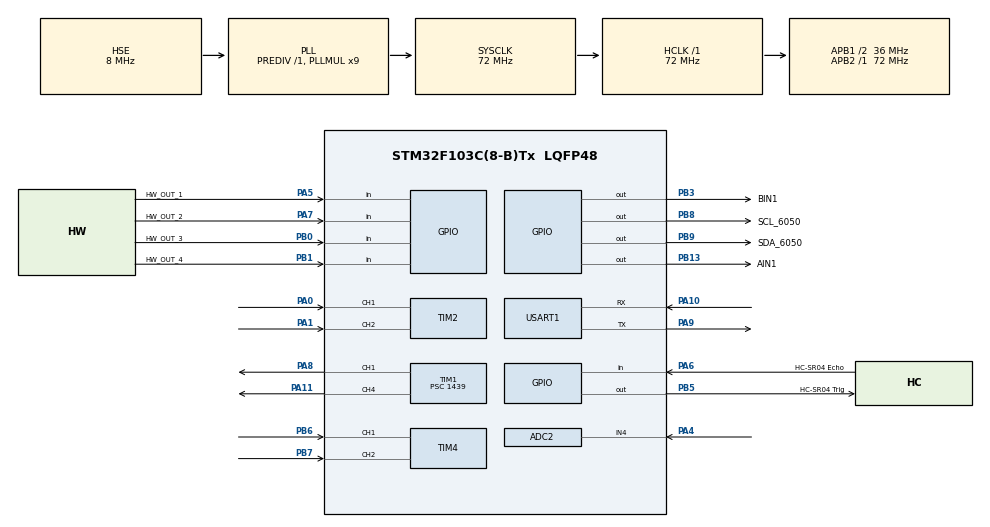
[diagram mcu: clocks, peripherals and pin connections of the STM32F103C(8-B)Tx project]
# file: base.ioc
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ADC2.Channel-0\#ChannelRegularConversion=ADC_CHANNEL_4
ADC2.NbrOfConversionFlag=1
ADC2.Rank-0\#ChannelRegularConversion=1
ADC2.SamplingTime-0\#ChannelRegularConversion=ADC_SAMPLETIME_13CYCLES_5
Mcu.Family=STM32F1
Mcu.Name=STM32F103C(8-B)Tx
Mcu.Package=LQFP48
NVIC.PriorityGroup=NVIC_PRIORITYGROUP_4
NVIC.TIM1_UP_IRQn=true\:0\:0\:false\:false\:true\:true\:true\:true
NVIC.TIM2_IRQn=true\:0\:0\:false\:false\:true\:true\:true\:true
NVIC.TIM4_IRQn=true\:0\:0\:false\:false\:true\:true\:true\:true
NVIC.USART1_IRQn=true\:0\:0\:false\:false\:true\:true\:true\:true
PA0-WKUP.GPIO_PuPd=GPIO_PULLUP
PA0-WKUP.Signal=S_TIM2_CH1_ETR
PA1.GPIO_PuPd=GPIO_PULLUP
PA1.Signal=S_TIM2_CH2
PA10.Mode=Asynchronous
PA10.Signal=USART1_RX
PA11.Signal=S_TIM1_CH4
PA13.Mode=Serial_Wire
PA13.Signal=SYS_JTMS-SWDIO
PA14.Mode=Serial_Wire
PA14.Signal=SYS_JTCK-SWCLK
PA4.Signal=ADCx_IN4
PA5.GPIO_Label=HW_OUT_1
PA5.Signal=GPIO_Input
PA6.GPIO_Label=HC-SR04 Echo
PA6.Signal=GPIO_Input
PA7.GPIO_Label=HW_OUT_2
PA7.Signal=GPIO_Input
PA8.Signal=S_TIM1_CH1
PA9.Mode=Asynchronous
PA9.Signal=USART1_TX
PB0.GPIO_Label=HW_OUT_3
PB0.Signal=GPIO_Input
PB1.GPIO_Label=HW_OUT_4
PB1.Signal=GPIO_Input
PB13.GPIO_Label=AIN1
PB13.Signal=GPIO_Output
PB3.GPIO_Label=BIN1
PB3.Signal=GPIO_Output
PB5.GPIO_Label=HC-SR04 Trig
PB5.Signal=GPIO_Output
PB6.GPIO_PuPd=GPIO_PULLUP
PB6.Signal=S_TIM4_CH1
PB7.GPIO_PuPd=GPIO_PULLUP
PB7.Signal=S_TIM4_CH2
PB8.GPIO_Label=SCL_6050
PB8.Signal=GPIO_Output
PB9.GPIO_Label=SDA_6050
PB9.Signal=GPIO_Output
PD0-OSC_IN.Mode=HSE-External-Oscillator
PD0-OSC_IN.Signal=RCC_OSC_IN
PD1-OSC_OUT.Mode=HSE-External-Oscillator
PD1-OSC_OUT.Signal=RCC_OSC_OUT
ProjectManager.HeapSize=0x200
ProjectManager.StackSize=0x400
ProjectManager.TargetToolchain=MDK-ARM V5.32
RCC.ADCPresc=RCC_ADCPCLK2_DIV6
RCC.AHBFreq_Value=72000000
RCC.APB1CLKDivider=RCC_HCLK_DIV2
RCC.APB1Freq_Value=36000000
RCC.APB1TimFreq_Value=72000000
RCC.APB2Freq_Value=72000000
RCC.APB2TimFreq_Value=72000000
RCC.HCLKFreq_Value=72000000
RCC.PLLMUL=RCC_PLL_MUL9
RCC.PLLSourceVirtual=RCC_PLLSOURCE_HSE
RCC.SYSCLKFreq_VALUE=72000000
RCC.SYSCLKSource=RCC_SYSCLKSOURCE_PLLCLK
RCC.USBFreq_Value=72000000
SH.ADCx_IN4.0=ADC2_IN4,IN4
SH.S_TIM1_CH1.0=TIM1_CH1,PWM Generation1 CH1
SH.S_TIM1_CH4.0=TIM1_CH4,PWM Generation4 CH4
SH.S_TIM2_CH1_ETR.0=TIM2_CH1,Encoder_Interface
SH.S_TIM2_CH2.0=TIM2_CH2,Encoder_Interface
SH.S_TIM4_CH1.0=TIM4_CH1,Encoder_Interface
SH.S_TIM4_CH2.0=TIM4_CH2,Encoder_Interface
TIM1.AutoReloadPreload=TIM_AUTORELOAD_PRELOAD_ENABLE
TIM1.Channel-PWM\ Generation1\ CH1=TIM_CHANNEL_1
TIM1.Channel-PWM\ Generation4\ CH4=TIM_CHANNEL_4
TIM1.Period=99
TIM1.Prescaler=1439
TIM1.Pulse-PWM\ Generation1\ CH1=50
TIM1.Pulse-PWM\ Generation4\ CH4=50
TIM2.EncoderMode=TIM_ENCODERMODE_TI12
TIM2.IC1Filter=6
TIM2.IC2Filter=6
TIM4.EncoderMode=TIM_ENCODERMODE_TI12
TIM4.IC1Filter=6
TIM4.IC2Filter=6
USART1.VirtualMode=VM_ASYNC
VP_TIM1_VS_ClockSourceINT.Mode=Internal
board=custom

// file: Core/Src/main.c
/* USER CODE BEGIN Header */
/**
  ******************************************************************************
  * @file           : main.c
  * @brief          : Main program body
  ******************************************************************************
  * @attention
  *
  * Copyright (c) 2026 STMicroelectronics.
  * All rights reserved.
  *
  * This software is licensed under terms that can be found in the LICENSE file
  * in the root directory of this software component.
  * If no LICENSE file comes with this software, it is provided AS-IS.
  *
  ******************************************************************************
  */
/* USER CODE END Header */
#include "main.h"
#include "adc.h"
#include "tim.h"
#include "usart.h"
#include "gpio.h"

/* USER CODE BEGIN Includes */
#include "motor.h"
#include "base_control.h"
#include "mpu6050.h"
/* USER CODE END Includes */

void SystemClock_Config(void);

int main(void)
{

  /* MCU Configuration--------------------------------------------------------*/

  /* Reset of all peripherals, Initializes the Flash interface and the Systick. */
  HAL_Init();

  /* Configure the system clock */
  SystemClock_Config();

  /* Initialize all configured peripherals */
  MX_GPIO_Init();
  MX_ADC2_Init();
  MX_TIM1_Init();
  MX_TIM2_Init();
  MX_TIM4_Init();
  MX_USART1_UART_Init();
  /* USER CODE BEGIN 2 */
  HAL_TIM_PWM_Start(&htim1, TIM_CHANNEL_1);       /* 启动电机 1 PWM 输出 */
  HAL_TIM_PWM_Start(&htim1, TIM_CHANNEL_4);       /* 启动电机 2 PWM 输出 */
  HAL_TIM_Encoder_Start(&htim2, TIM_CHANNEL_ALL); /* 启动编码器 2 计数 */
  HAL_TIM_Encoder_Start(&htim4, TIM_CHANNEL_ALL); /* 启动编码器 1 计数 */

  BaseControl_Stop();                             /* 上电默认停车，等待树莓派 USART1 命令 */
  BaseCmd_StartReceive();                         /* 开启 USART1 单字节中断接收 */

  HAL_Delay(500);                                 /* 等待 MPU6050 上电稳定 */
  (void)MPU_Init();

  /* USER CODE END 2 */

  /* Infinite loop */
  while (1)
  {

    /* USER CODE BEGIN 3 */
    BaseCmd_Task();                               /* 处理树莓派发来的完整底盘命令帧 */
    BaseControl_Task();                           /* 执行底盘状态机、循迹和安全停车任务 */
    HAL_Delay(10);
  }
  /* USER CODE END 3 */
}

void SystemClock_Config(void)
{
  RCC_OscInitTypeDef RCC_OscInitStruct = {0};
  RCC_ClkInitTypeDef RCC_ClkInitStruct = {0};
  RCC_PeriphCLKInitTypeDef PeriphClkInit = {0};

  /** Initializes the RCC Oscillators according to the specified parameters
  * in the RCC_OscInitTypeDef structure.
  */
  RCC_OscInitStruct.OscillatorType = RCC_OSCILLATORTYPE_HSE;
  RCC_OscInitStruct.HSEState = RCC_HSE_ON;
  RCC_OscInitStruct.HSEPredivValue = RCC_HSE_PREDIV_DIV1;
  RCC_OscInitStruct.HSIState = RCC_HSI_ON;
  RCC_OscInitStruct.PLL.PLLState = RCC_PLL_ON;
  RCC_OscInitStruct.PLL.PLLSource = RCC_PLLSOURCE_HSE;
  RCC_OscInitStruct.PLL.PLLMUL = RCC_PLL_MUL9;
  if (HAL_RCC_OscConfig(&RCC_OscInitStruct) != HAL_OK)
  {
    Error_Handler();
  }

  /** Initializes the CPU, AHB and APB buses clocks
  */
  RCC_ClkInitStruct.ClockType = RCC_CLOCKTYPE_HCLK|RCC_CLOCKTYPE_SYSCLK
                              |RCC_CLOCKTYPE_PCLK1|RCC_CLOCKTYPE_PCLK2;
  RCC_ClkInitStruct.SYSCLKSource = RCC_SYSCLKSOURCE_PLLCLK;
  RCC_ClkInitStruct.AHBCLKDivider = RCC_SYSCLK_DIV1;
  RCC_ClkInitStruct.APB1CLKDivider = RCC_HCLK_DIV2;
  RCC_ClkInitStruct.APB2CLKDivider = RCC_HCLK_DIV1;

  if (HAL_RCC_ClockConfig(&RCC_ClkInitStruct, FLASH_LATENCY_2) != HAL_OK)
  {
    Error_Handler();
  }
  PeriphClkInit.PeriphClockSelection = RCC_PERIPHCLK_ADC;
  PeriphClkInit.AdcClockSelection = RCC_ADCPCLK2_DIV6;
  if (HAL_RCCEx_PeriphCLKConfig(&PeriphClkInit) != HAL_OK)
  {
    Error_Handler();
  }
}

void Error_Handler(void)
{
  __disable_irq();
  while (1)
  {
  }
}
